VERSION "dbc-export 1 2025.20.8"

NS_ :

BS_:

BU_: APS DAS PARK

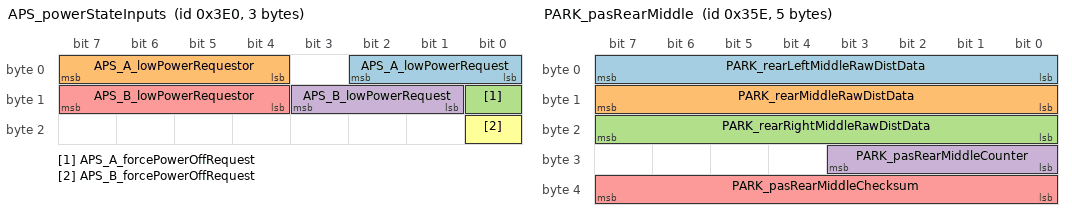
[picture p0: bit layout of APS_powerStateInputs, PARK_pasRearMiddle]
BO_ 992 APS_powerStateInputs: 3 APS
 SG_ APS_A_lowPowerRequest : 0|3@1+ (1,0) [0|7] "" Vector__XXX
 SG_ APS_A_lowPowerRequestor : 4|4@1+ (1,0) [0|15] "" Vector__XXX
 SG_ APS_A_forcePowerOffRequest : 8|1@1+ (1,0) [0|1] "" Vector__XXX
 SG_ APS_B_lowPowerRequest : 9|3@1+ (1,0) [0|7] "" Vector__XXX
 SG_ APS_B_lowPowerRequestor : 12|4@1+ (1,0) [0|15] "" Vector__XXX
 SG_ APS_B_forcePowerOffRequest : 16|1@1+ (1,0) [0|1] "" Vector__XXX

BO_ 586 DAS_visualDebug: 8 DAS
 SG_ DAS_autosteerVehiclesUsage : 4|2@1+ (1,0) [0|3] "" Vector__XXX
 SG_ DAS_autosteerHPPUsage : 6|2@1+ (1,0) [0|3] "" Vector__XXX
 SG_ DAS_autosteerNavigationUsage : 8|2@1+ (1,0) [0|3] "" Vector__XXX
 SG_ DAS_autosteerModelUsage : 10|2@1+ (1,0) [0|3] "" Vector__XXX
 SG_ DAS_autosteerBottsDotsUsage : 12|2@1+ (1,0) [0|3] "" Vector__XXX
 SG_ DAS_offsetSide : 14|2@1+ (1,0) [0|3] "" Vector__XXX
 SG_ DAS_roadSurfaceType : 16|2@1+ (1,0) [1|3] "" Vector__XXX
 SG_ DAS_autosteerHealthAnomalyLevel : 18|3@1+ (1,0) [0|7] "" Vector__XXX
 SG_ DAS_autosteerHealthState : 21|3@1+ (1,0) [0|7] "" Vector__XXX
 SG_ DAS_lastLinePreferenceReason : 24|4@1+ (1,0) [0|15] "" Vector__XXX
 SG_ DAS_plannerState : 28|4@1+ (1,0) [0|15] "" Vector__XXX
 SG_ DAS_lastAutosteerAbortReason : 32|6@1+ (1,0) [0|63] "" Vector__XXX
 SG_ DAS_devAppInterfaceEnabled : 38|1@1+ (1,0) [0|1] "" Vector__XXX
 SG_ DAS_navAvailable : 39|1@1+ (1,0) [0|1] "" Vector__XXX
 SG_ DAS_navDistance : 40|8@1+ (100,0) [0|25500] "km" Vector__XXX
 SG_ DAS_accSmartSpeedActive : 48|1@1+ (1,0) [0|1] "" Vector__XXX
 SG_ DAS_accSmartSpeedState : 49|3@1+ (1,0) [0|6] "" Vector__XXX
 SG_ DAS_ulcInProgress : 52|1@1+ (1,0) [0|1] "" Vector__XXX
 SG_ DAS_trafficAwareSetSpeedInUse : 53|1@1+ (1,0) [0|1] "" Vector__XXX
 SG_ DAS_isaSystemState : 54|2@1+ (1,0) [0|3] "" Vector__XXX
 SG_ DAS_behaviorType : 56|2@1+ (1,0) [0|3] "" Vector__XXX
 SG_ DAS_ulcType : 58|2@1+ (1,0) [0|3] "" Vector__XXX
 SG_ DAS_rearVehDetectedThisCycle : 60|1@1+ (1,0) [0|1] "" Vector__XXX
 SG_ DAS_rearLeftVehDetectedCurrent : 61|1@1+ (1,0) [0|1] "" Vector__XXX
 SG_ DAS_rearRightVehDetectedTrip : 62|1@1+ (1,0) [0|1] "" Vector__XXX
 SG_ DAS_rearLeftVehDetectedTrip : 63|1@1+ (1,0) [0|1] "" Vector__XXX

BO_ 862 PARK_pasRearMiddle: 5 PARK
 SG_ PARK_rearLeftMiddleRawDistData : 0|8@1+ (1,0) [0|254] "cm" Vector__XXX
 SG_ PARK_rearMiddleRawDistData : 8|8@1+ (1,0) [0|254] "cm" Vector__XXX
 SG_ PARK_rearRightMiddleRawDistData : 16|8@1+ (1,0) [0|254] "cm" Vector__XXX
 SG_ PARK_pasRearMiddleCounter : 24|4@1+ (1,0) [0|15] "" Vector__XXX
 SG_ PARK_pasRearMiddleChecksum : 32|8@1+ (1,0) [0|255] "" Vector__XXX

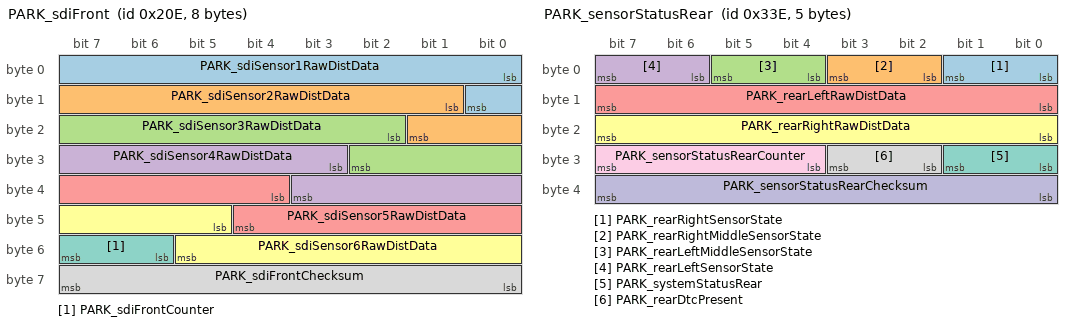
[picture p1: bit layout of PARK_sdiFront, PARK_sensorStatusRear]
BO_ 526 PARK_sdiFront: 8 PARK
 SG_ PARK_sdiSensor1RawDistData : 0|9@1+ (1,0) [0|510] "cm" Vector__XXX
 SG_ PARK_sdiSensor2RawDistData : 9|9@1+ (1,0) [0|510] "cm" Vector__XXX
 SG_ PARK_sdiSensor3RawDistData : 18|9@1+ (1,0) [0|510] "cm" Vector__XXX
 SG_ PARK_sdiSensor4RawDistData : 27|9@1+ (1,0) [0|510] "cm" Vector__XXX
 SG_ PARK_sdiSensor5RawDistData : 36|9@1+ (1,0) [0|510] "cm" Vector__XXX
 SG_ PARK_sdiSensor6RawDistData : 45|9@1+ (1,0) [0|510] "cm" Vector__XXX
 SG_ PARK_sdiFrontCounter : 54|2@1+ (1,0) [0|3] "" Vector__XXX
 SG_ PARK_sdiFrontChecksum : 56|8@1+ (1,0) [0|255] "" Vector__XXX

BO_ 830 PARK_sensorStatusRear: 5 PARK
 SG_ PARK_rearRightSensorState : 0|2@1+ (1,0) [0|2] "" Vector__XXX
 SG_ PARK_rearRightMiddleSensorState : 2|2@1+ (1,0) [0|2] "" Vector__XXX
 SG_ PARK_rearLeftMiddleSensorState : 4|2@1+ (1,0) [0|2] "" Vector__XXX
 SG_ PARK_rearLeftSensorState : 6|2@1+ (1,0) [0|2] "" Vector__XXX
 SG_ PARK_rearLeftRawDistData : 8|8@1+ (1,0) [0|254] "cm" Vector__XXX
 SG_ PARK_rearRightRawDistData : 16|8@1+ (1,0) [0|254] "cm" Vector__XXX
 SG_ PARK_systemStatusRear : 24|2@1+ (1,0) [0|2] "" Vector__XXX
 SG_ PARK_rearDtcPresent : 26|2@1+ (1,0) [0|2] "" Vector__XXX
 SG_ PARK_sensorStatusRearCounter : 28|4@1+ (1,0) [0|15] "" Vector__XXX
 SG_ PARK_sensorStatusRearChecksum : 32|8@1+ (1,0) [0|255] "" Vector__XXX

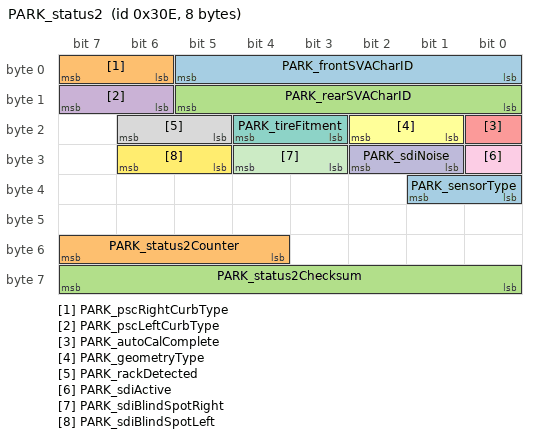
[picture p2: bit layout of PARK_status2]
BO_ 782 PARK_status2: 8 PARK
 SG_ PARK_frontSVACharID : 0|6@1+ (1,0) [0|63] "" Vector__XXX
 SG_ PARK_pscRightCurbType : 6|2@1+ (1,0) [0|3] "" Vector__XXX
 SG_ PARK_rearSVACharID : 8|6@1+ (1,0) [0|63] "" Vector__XXX
 SG_ PARK_pscLeftCurbType : 14|2@1+ (1,0) [0|3] "" Vector__XXX
 SG_ PARK_autoCalComplete : 16|1@1+ (1,0) [0|1] "" Vector__XXX
 SG_ PARK_geometryType : 17|2@1+ (1,0) [0|3] "" Vector__XXX
 SG_ PARK_tireFitment : 19|2@1+ (1,0) [0|2] "" Vector__XXX
 SG_ PARK_rackDetected : 21|2@1+ (1,0) [0|2] "" Vector__XXX
 SG_ PARK_sdiActive : 24|1@1+ (1,0) [0|1] "" Vector__XXX
 SG_ PARK_sdiNoise : 25|2@1+ (1,0) [0|2] "" Vector__XXX
 SG_ PARK_sdiBlindSpotRight : 27|2@1+ (1,0) [0|2] "" Vector__XXX
 SG_ PARK_sdiBlindSpotLeft : 29|2@1+ (1,0) [0|2] "" Vector__XXX
 SG_ PARK_sensorType : 32|2@1+ (1,0) [0|2] "" Vector__XXX
 SG_ PARK_status2Counter : 52|4@1+ (1,0) [0|15] "" Vector__XXX
 SG_ PARK_status2Checksum : 56|8@1+ (1,0) [0|255] "" Vector__XXX

BO_TX_BU_ 992 : APS;
BO_TX_BU_ 586 : DAS;
BO_TX_BU_ 862 : PARK;
BO_TX_BU_ 526 : PARK;
BO_TX_BU_ 830 : PARK;
BO_TX_BU_ 782 : PARK;

CM_ "Tesla Model Y CAN bus database; bus CH (chassis CAN); firmware 2025.20.8. Decoded CAN signal definitions (layout, scaling, units, value tables).";
CM_ BU_ APS "Driver assistance computer (secondary)";
CM_ BU_ DAS "Driver assistance computer";
CM_ BU_ PARK "Parking assist sensors";
CM_ BO_ 992 "Driver assistance computer (secondary) message: power state inputs";
CM_ SG_ 992 APS_A_lowPowerRequest "Indicates Autopilot Secondary Processor (APS) low power state request presence.";
CM_ SG_ 992 APS_A_lowPowerRequestor "Indicates who initiated the Autopilot Secondary Processor (APS) low power request.";
CM_ SG_ 992 APS_A_forcePowerOffRequest "Driver assistance computer (secondary): a force power off request";
CM_ SG_ 992 APS_B_lowPowerRequest "Indicates Autopilot Secondary Processor (APS) low power state request presence.";
CM_ SG_ 992 APS_B_lowPowerRequestor "Indicates who initiated the Autopilot Secondary Processor (APS) low power request.";
CM_ SG_ 992 APS_B_forcePowerOffRequest "Driver assistance computer (secondary): b force power off request";
CM_ BO_ 586 "Driver assistance computer message: visual debug";
CM_ SG_ 586 DAS_autosteerVehiclesUsage "Driver assistance computer: autosteer vehicles usage";
CM_ SG_ 586 DAS_autosteerHPPUsage "Driver assistance computer: autosteer HPP usage";
CM_ SG_ 586 DAS_autosteerNavigationUsage "Driver assistance computer: autosteer navigation usage";
CM_ SG_ 586 DAS_autosteerModelUsage "Driver assistance computer: autosteer model usage";
CM_ SG_ 586 DAS_autosteerBottsDotsUsage "Driver assistance computer: autosteer botts dots usage";
CM_ SG_ 586 DAS_offsetSide "Driver assistance computer: offset side";
CM_ SG_ 586 DAS_roadSurfaceType "Driver assistance computer: road surface type; raw 0 = signal not available (SNA)";
CM_ SG_ 586 DAS_autosteerHealthAnomalyLevel "Driver assistance computer: autosteer health anomaly level";
CM_ SG_ 586 DAS_autosteerHealthState "Driver assistance computer: autosteer health state";
CM_ SG_ 586 DAS_lastLinePreferenceReason "Driver assistance computer: last line preference reason";
CM_ SG_ 586 DAS_plannerState "Driver assistance computer: planner state";
CM_ SG_ 586 DAS_lastAutosteerAbortReason "Driver assistance computer: last autosteer abort reason";
CM_ SG_ 586 DAS_devAppInterfaceEnabled "Driver assistance computer: dev app interface enabled";
CM_ SG_ 586 DAS_navAvailable "Driver assistance computer: nav available";
CM_ SG_ 586 DAS_navDistance "Driver assistance computer: nav distance";
CM_ SG_ 586 DAS_accSmartSpeedActive "Driver assistance computer: acc smart speed active";
CM_ SG_ 586 DAS_accSmartSpeedState "Driver assistance computer: acc smart speed state; raw 7 = signal not available (SNA)";
CM_ SG_ 586 DAS_ulcInProgress "Reports active lane changes that were not commanded.";
CM_ SG_ 586 DAS_trafficAwareSetSpeedInUse "Indicates that autopilot is using cruise set speed based on flow of traffic";
CM_ SG_ 586 DAS_isaSystemState "ISA system state";
CM_ SG_ 586 DAS_behaviorType "Driver assistance computer: behavior type";
CM_ SG_ 586 DAS_ulcType "Reports the underlying reason for the uncommanded lane change, whether for speed or route.";
CM_ SG_ 586 DAS_rearVehDetectedThisCycle "Driver assistance computer: rear veh detected this cycle";
CM_ SG_ 586 DAS_rearLeftVehDetectedCurrent "Driver assistance computer: rear left veh detected current";
CM_ SG_ 586 DAS_rearRightVehDetectedTrip "Driver assistance computer: rear right veh detected trip";
CM_ SG_ 586 DAS_rearLeftVehDetectedTrip "Driver assistance computer: rear left veh detected trip";
CM_ BO_ 862 "Parking assist sensors message: pas rear middle";
CM_ SG_ 862 PARK_rearLeftMiddleRawDistData "Zone defined as -124 degrees to -166 degrees, distance to object in units of centimeters; raw 255 = signal not available (SNA)";
CM_ SG_ 862 PARK_rearMiddleRawDistData "Zone defined as -166 degrees to +166 degrees, distance to object in units of centimeters; raw 255 = signal not available (SNA)";
CM_ SG_ 862 PARK_rearRightMiddleRawDistData "Zone defined as +166 degrees to +124 degrees, distance to object in units of centimeters; raw 255 = signal not available (SNA)";
CM_ SG_ 862 PARK_pasRearMiddleCounter "Parking assist sensors: pas rear middle counter";
CM_ SG_ 862 PARK_pasRearMiddleChecksum "Parking assist sensors: pas rear middle checksum";
CM_ BO_ 526 "Parking assist sensors message: sdi front";
CM_ SG_ 526 PARK_sdiSensor1RawDistData "Parking assist sensors: sdi sensor1 raw dist data; raw 511 = signal not available (SNA)";
CM_ SG_ 526 PARK_sdiSensor2RawDistData "Parking assist sensors: sdi sensor2 raw dist data; raw 511 = signal not available (SNA)";
CM_ SG_ 526 PARK_sdiSensor3RawDistData "Parking assist sensors: sdi sensor3 raw dist data; raw 511 = signal not available (SNA)";
CM_ SG_ 526 PARK_sdiSensor4RawDistData "Parking assist sensors: sdi sensor4 raw dist data; raw 511 = signal not available (SNA)";
CM_ SG_ 526 PARK_sdiSensor5RawDistData "Parking assist sensors: sdi sensor5 raw dist data; raw 511 = signal not available (SNA)";
CM_ SG_ 526 PARK_sdiSensor6RawDistData "Parking assist sensors: sdi sensor6 raw dist data; raw 511 = signal not available (SNA)";
CM_ SG_ 526 PARK_sdiFrontCounter "Parking assist sensors: sdi front counter";
CM_ SG_ 526 PARK_sdiFrontChecksum "Parking assist sensors: sdi front checksum";
CM_ BO_ 830 "Parking assist sensors message: sensor status rear";
CM_ SG_ 830 PARK_rearRightSensorState "Reports the state of the rear right ultrasonic sensor; raw 3 = signal not available (SNA)";
CM_ SG_ 830 PARK_rearRightMiddleSensorState "Reports the state of the rear right middle ultrasonic sensor; raw 3 = signal not available (SNA)";
CM_ SG_ 830 PARK_rearLeftMiddleSensorState "Reports the state of the rear left middle ultrasonic sensor; raw 3 = signal not available (SNA)";
CM_ SG_ 830 PARK_rearLeftSensorState "Reports the state of the rear left ultrasonic sensor; raw 3 = signal not available (SNA)";
CM_ SG_ 830 PARK_rearLeftRawDistData "Zone defined as -90 degrees to -125 degrees, distance to object in units of centimeters; raw 255 = signal not available (SNA)";
CM_ SG_ 830 PARK_rearRightRawDistData "Zone defined as +125 degrees to +90 degrees, distance to object in units of centimeters; raw 255 = signal not available (SNA)";
CM_ SG_ 830 PARK_systemStatusRear "Parking assist sensors: system status rear; raw 3 = signal not available (SNA)";
CM_ SG_ 830 PARK_rearDtcPresent "Parking assist sensors: rear dtc present; raw 3 = signal not available (SNA)";
CM_ SG_ 830 PARK_sensorStatusRearCounter "Parking assist sensors: sensor status rear counter";
CM_ SG_ 830 PARK_sensorStatusRearChecksum "Parking assist sensors: sensor status rear checksum";
CM_ BO_ 782 "Parking assist sensors message: status2";
CM_ SG_ 782 PARK_frontSVACharID "Parking assist sensors: front SVA char ID";
CM_ SG_ 782 PARK_pscRightCurbType "The type of curb for the parallel parking slot on the right side.";
CM_ SG_ 782 PARK_rearSVACharID "Parking assist sensors: rear SVA char ID";
CM_ SG_ 782 PARK_pscLeftCurbType "The type of curb identified for a parallel parking space on the left.";
CM_ SG_ 782 PARK_autoCalComplete "Parking assist sensors: auto cal complete";
CM_ SG_ 782 PARK_geometryType "Parking assist sensors: geometry type";
CM_ SG_ 782 PARK_tireFitment "Parking assist sensors: tire fitment; raw 3 = signal not available (SNA)";
CM_ SG_ 782 PARK_rackDetected "Parking assist sensors: rack detected; raw 3 = signal not available (SNA)";
CM_ SG_ 782 PARK_sdiActive "Whether or not the raw sensor measurements from the ultrasonics are present and valid";
CM_ SG_ 782 PARK_sdiNoise "The output of the noise detection algorithm for raw sensor measurements, indicates if the measurements are degraded due to ambient noise; raw 3 = signal not available (SNA)";
CM_ SG_ 782 PARK_sdiBlindSpotRight "The output of the PARK ECU blindspot algorithm on the right side of the car, indicates the presence of a vehicle; raw 3 = signal not available (SNA)";
CM_ SG_ 782 PARK_sdiBlindSpotLeft "The output of the PARK ECU blindspot algorithm on the left side of the car, indicates the presence of a vehicle; raw 3 = signal not available (SNA)";
CM_ SG_ 782 PARK_sensorType "Parking assist sensors: sensor type; raw 3 = signal not available (SNA)";
CM_ SG_ 782 PARK_status2Counter "Parking assist sensors: status2 counter";
CM_ SG_ 782 PARK_status2Checksum "Parking assist sensors: status2 checksum";
BA_DEF_ "BusType" STRING;
BA_DEF_ "DBName" STRING;
BA_DEF_ "Baudrate" INT 0 1000000;
BA_DEF_ "BaudrateCANFD" INT 0 16000000;
BA_DEF_ "Manufacturer" STRING;
BA_DEF_ "FirmwareVersion" STRING;
BA_DEF_ "VehicleModel" STRING;
BA_DEF_ BU_ "ECU" STRING;
BA_DEF_ BO_ "GenMsgCycleTime" INT 0 3600000;
BA_DEF_ BO_ "GenMsgSendType" ENUM "Cyclic","NotUsed","NotUsed","NotUsed","NotUsed","NotUsed","NotUsed","IfActive","NoMsgSendType","NotUsed";
BA_DEF_ BO_ "VFrameFormat" ENUM "StandardCAN","ExtendedCAN","reserved","J1939PG","reserved","reserved","reserved","reserved","reserved","reserved","reserved","reserved","reserved","reserved","StandardCAN_FD","ExtendedCAN_FD";
BA_DEF_ BO_ "CANFD_BRS" ENUM "0","1";
BA_DEF_ SG_ "GenSigSNA" STRING;
BA_DEF_ SG_ "Confidence" ENUM "validated","plausible","layout-only","contradicted";
BA_DEF_DEF_ "BusType" "CAN";
BA_DEF_DEF_ "DBName" "";
BA_DEF_DEF_ "Baudrate" 500000;
BA_DEF_DEF_ "BaudrateCANFD" 2000000;
BA_DEF_DEF_ "Manufacturer" "";
BA_DEF_DEF_ "FirmwareVersion" "";
BA_DEF_DEF_ "VehicleModel" "";
BA_DEF_DEF_ "ECU" "";
BA_DEF_DEF_ "GenMsgCycleTime" 0;
BA_DEF_DEF_ "GenMsgSendType" "NoMsgSendType";
BA_DEF_DEF_ "VFrameFormat" "StandardCAN";
BA_DEF_DEF_ "CANFD_BRS" "1";
BA_DEF_DEF_ "GenSigSNA" "";
BA_DEF_DEF_ "Confidence" "layout-only";
BA_ "DBName" "ModelY_CH";
BA_ "Manufacturer" "Tesla";
BA_ "FirmwareVersion" "2025.20.8";
BA_ "VehicleModel" "Model Y";
BA_ "ECU" BU_ APS "APS";
BA_ "ECU" BU_ DAS "DAS";
BA_ "ECU" BU_ PARK "PARK";
BA_ "GenMsgCycleTime" BO_ 992 100;
BA_ "GenMsgSendType" BO_ 992 0;
BA_ "GenMsgCycleTime" BO_ 586 100;
BA_ "GenMsgSendType" BO_ 586 0;
BA_ "GenMsgCycleTime" BO_ 862 100;
BA_ "GenMsgSendType" BO_ 862 0;
BA_ "GenMsgCycleTime" BO_ 526 40;
BA_ "GenMsgSendType" BO_ 526 0;
BA_ "GenMsgCycleTime" BO_ 830 100;
BA_ "GenMsgSendType" BO_ 830 0;
BA_ "GenMsgCycleTime" BO_ 782 250;
BA_ "GenMsgSendType" BO_ 782 0;
BA_ "Confidence" SG_ 992 APS_A_lowPowerRequest 0;
BA_ "Confidence" SG_ 992 APS_A_lowPowerRequestor 0;
BA_ "Confidence" SG_ 992 APS_A_forcePowerOffRequest 0;
BA_ "Confidence" SG_ 992 APS_B_lowPowerRequest 0;
BA_ "Confidence" SG_ 992 APS_B_lowPowerRequestor 0;
BA_ "Confidence" SG_ 992 APS_B_forcePowerOffRequest 0;
BA_ "Confidence" SG_ 586 DAS_autosteerVehiclesUsage 0;
BA_ "Confidence" SG_ 586 DAS_autosteerHPPUsage 0;
BA_ "Confidence" SG_ 586 DAS_autosteerNavigationUsage 0;
BA_ "Confidence" SG_ 586 DAS_autosteerModelUsage 0;
BA_ "Confidence" SG_ 586 DAS_autosteerBottsDotsUsage 0;
BA_ "Confidence" SG_ 586 DAS_offsetSide 0;
BA_ "Confidence" SG_ 586 DAS_roadSurfaceType 0;
BA_ "GenSigSNA" SG_ 586 DAS_roadSurfaceType "0";
BA_ "Confidence" SG_ 586 DAS_autosteerHealthAnomalyLevel 0;
BA_ "Confidence" SG_ 586 DAS_autosteerHealthState 0;
BA_ "Confidence" SG_ 586 DAS_lastLinePreferenceReason 0;
BA_ "Confidence" SG_ 586 DAS_plannerState 0;
BA_ "Confidence" SG_ 586 DAS_lastAutosteerAbortReason 0;
BA_ "Confidence" SG_ 586 DAS_devAppInterfaceEnabled 0;
BA_ "Confidence" SG_ 586 DAS_navAvailable 0;
BA_ "Confidence" SG_ 586 DAS_navDistance 0;
BA_ "Confidence" SG_ 586 DAS_accSmartSpeedActive 0;
BA_ "Confidence" SG_ 586 DAS_accSmartSpeedState 0;
BA_ "GenSigSNA" SG_ 586 DAS_accSmartSpeedState "7";
BA_ "Confidence" SG_ 586 DAS_ulcInProgress 0;
BA_ "Confidence" SG_ 586 DAS_trafficAwareSetSpeedInUse 0;
BA_ "Confidence" SG_ 586 DAS_isaSystemState 0;
BA_ "Confidence" SG_ 586 DAS_behaviorType 0;
BA_ "Confidence" SG_ 586 DAS_ulcType 0;
BA_ "Confidence" SG_ 586 DAS_rearVehDetectedThisCycle 0;
BA_ "Confidence" SG_ 586 DAS_rearLeftVehDetectedCurrent 0;
BA_ "Confidence" SG_ 586 DAS_rearRightVehDetectedTrip 0;
BA_ "Confidence" SG_ 586 DAS_rearLeftVehDetectedTrip 0;
BA_ "Confidence" SG_ 862 PARK_rearLeftMiddleRawDistData 0;
BA_ "GenSigSNA" SG_ 862 PARK_rearLeftMiddleRawDistData "255";
BA_ "Confidence" SG_ 862 PARK_rearMiddleRawDistData 0;
BA_ "GenSigSNA" SG_ 862 PARK_rearMiddleRawDistData "255";
BA_ "Confidence" SG_ 862 PARK_rearRightMiddleRawDistData 0;
BA_ "GenSigSNA" SG_ 862 PARK_rearRightMiddleRawDistData "255";
BA_ "Confidence" SG_ 862 PARK_pasRearMiddleCounter 0;
BA_ "Confidence" SG_ 862 PARK_pasRearMiddleChecksum 0;
BA_ "Confidence" SG_ 526 PARK_sdiSensor1RawDistData 0;
BA_ "GenSigSNA" SG_ 526 PARK_sdiSensor1RawDistData "511";
BA_ "Confidence" SG_ 526 PARK_sdiSensor2RawDistData 0;
BA_ "GenSigSNA" SG_ 526 PARK_sdiSensor2RawDistData "511";
BA_ "Confidence" SG_ 526 PARK_sdiSensor3RawDistData 0;
BA_ "GenSigSNA" SG_ 526 PARK_sdiSensor3RawDistData "511";
BA_ "Confidence" SG_ 526 PARK_sdiSensor4RawDistData 0;
BA_ "GenSigSNA" SG_ 526 PARK_sdiSensor4RawDistData "511";
BA_ "Confidence" SG_ 526 PARK_sdiSensor5RawDistData 0;
BA_ "GenSigSNA" SG_ 526 PARK_sdiSensor5RawDistData "511";
BA_ "Confidence" SG_ 526 PARK_sdiSensor6RawDistData 0;
BA_ "GenSigSNA" SG_ 526 PARK_sdiSensor6RawDistData "511";
BA_ "Confidence" SG_ 526 PARK_sdiFrontCounter 0;
BA_ "Confidence" SG_ 526 PARK_sdiFrontChecksum 0;
BA_ "Confidence" SG_ 830 PARK_rearRightSensorState 0;
BA_ "GenSigSNA" SG_ 830 PARK_rearRightSensorState "3";
BA_ "Confidence" SG_ 830 PARK_rearRightMiddleSensorState 0;
BA_ "GenSigSNA" SG_ 830 PARK_rearRightMiddleSensorState "3";
BA_ "Confidence" SG_ 830 PARK_rearLeftMiddleSensorState 0;
BA_ "GenSigSNA" SG_ 830 PARK_rearLeftMiddleSensorState "3";
BA_ "Confidence" SG_ 830 PARK_rearLeftSensorState 0;
BA_ "GenSigSNA" SG_ 830 PARK_rearLeftSensorState "3";
BA_ "Confidence" SG_ 830 PARK_rearLeftRawDistData 0;
BA_ "GenSigSNA" SG_ 830 PARK_rearLeftRawDistData "255";
BA_ "Confidence" SG_ 830 PARK_rearRightRawDistData 0;
BA_ "GenSigSNA" SG_ 830 PARK_rearRightRawDistData "255";
BA_ "Confidence" SG_ 830 PARK_systemStatusRear 0;
BA_ "GenSigSNA" SG_ 830 PARK_systemStatusRear "3";
BA_ "Confidence" SG_ 830 PARK_rearDtcPresent 0;
BA_ "GenSigSNA" SG_ 830 PARK_rearDtcPresent "3";
BA_ "Confidence" SG_ 830 PARK_sensorStatusRearCounter 0;
BA_ "Confidence" SG_ 830 PARK_sensorStatusRearChecksum 0;
BA_ "Confidence" SG_ 782 PARK_frontSVACharID 0;
BA_ "Confidence" SG_ 782 PARK_pscRightCurbType 0;
BA_ "Confidence" SG_ 782 PARK_rearSVACharID 0;
BA_ "Confidence" SG_ 782 PARK_pscLeftCurbType 0;
BA_ "Confidence" SG_ 782 PARK_autoCalComplete 0;
BA_ "Confidence" SG_ 782 PARK_geometryType 0;
BA_ "Confidence" SG_ 782 PARK_tireFitment 0;
BA_ "GenSigSNA" SG_ 782 PARK_tireFitment "3";
BA_ "Confidence" SG_ 782 PARK_rackDetected 0;
BA_ "GenSigSNA" SG_ 782 PARK_rackDetected "3";
BA_ "Confidence" SG_ 782 PARK_sdiActive 0;
BA_ "Confidence" SG_ 782 PARK_sdiNoise 0;
BA_ "GenSigSNA" SG_ 782 PARK_sdiNoise "3";
BA_ "Confidence" SG_ 782 PARK_sdiBlindSpotRight 0;
BA_ "GenSigSNA" SG_ 782 PARK_sdiBlindSpotRight "3";
BA_ "Confidence" SG_ 782 PARK_sdiBlindSpotLeft 0;
BA_ "GenSigSNA" SG_ 782 PARK_sdiBlindSpotLeft "3";
BA_ "Confidence" SG_ 782 PARK_sensorType 0;
BA_ "GenSigSNA" SG_ 782 PARK_sensorType "3";
BA_ "Confidence" SG_ 782 PARK_status2Counter 0;
BA_ "Confidence" SG_ 782 PARK_status2Checksum 0;
VAL_ 992 APS_A_lowPowerRequest 5 "APS_LOW_POWER_COLD_RESET" 4 "APS_LOW_POWER_SOC_WARM_RESET" 3 "APS_LOW_POWER_AP_WARM_RESET" 2 "APS_LOW_POWER_OFF" 1 "APS_LOW_POWER_SUSPEND" 0 "APS_LOW_POWER_NONE" ;
VAL_ 992 APS_A_lowPowerRequestor 10 "APS_LOW_POWER_REQ_COUNT" 9 "APS_LOW_POWER_REQ_SGK_PGOOD_IRQ" 8 "APS_LOW_POWER_REQ_SGK_CONSOLE" 7 "APS_LOW_POWER_REQ_SGK_SLEEP" 6 "APS_LOW_POWER_REQ_SGK_UDS" 5 "APS_LOW_POWER_REQ_SGK_BRIDGE" 4 "APS_LOW_POWER_REQ_SGK_FM" 3 "APS_LOW_POWER_REQ_SGK_POWER" 2 "APS_LOW_POWER_REQ_AP_MAILBOX" 1 "APS_LOW_POWER_REQ_AP_ATF" 0 "APS_LOW_POWER_REQ_NONE" ;
VAL_ 992 APS_B_lowPowerRequest 5 "APS_LOW_POWER_COLD_RESET" 4 "APS_LOW_POWER_SOC_WARM_RESET" 3 "APS_LOW_POWER_AP_WARM_RESET" 2 "APS_LOW_POWER_OFF" 1 "APS_LOW_POWER_SUSPEND" 0 "APS_LOW_POWER_NONE" ;
VAL_ 992 APS_B_lowPowerRequestor 10 "APS_LOW_POWER_REQ_COUNT" 9 "APS_LOW_POWER_REQ_SGK_PGOOD_IRQ" 8 "APS_LOW_POWER_REQ_SGK_CONSOLE" 7 "APS_LOW_POWER_REQ_SGK_SLEEP" 6 "APS_LOW_POWER_REQ_SGK_UDS" 5 "APS_LOW_POWER_REQ_SGK_BRIDGE" 4 "APS_LOW_POWER_REQ_SGK_FM" 3 "APS_LOW_POWER_REQ_SGK_POWER" 2 "APS_LOW_POWER_REQ_AP_MAILBOX" 1 "APS_LOW_POWER_REQ_AP_ATF" 0 "APS_LOW_POWER_REQ_NONE" ;
VAL_ 586 DAS_autosteerVehiclesUsage 3 "BLACKLISTED" 2 "FUSED" 1 "AVAILABLE" 0 "REJECTED_UNAVAILABLE" ;
VAL_ 586 DAS_autosteerHPPUsage 3 "BLACKLISTED" 2 "FUSED" 1 "AVAILABLE" 0 "REJECTED_UNAVAILABLE" ;
VAL_ 586 DAS_autosteerNavigationUsage 3 "BLACKLISTED" 2 "FUSED" 1 "AVAILABLE" 0 "REJECTED_UNAVAILABLE" ;
VAL_ 586 DAS_autosteerModelUsage 3 "BLACKLISTED" 2 "FUSED" 1 "AVAILABLE" 0 "REJECTED_UNAVAILABLE" ;
VAL_ 586 DAS_autosteerBottsDotsUsage 3 "BLACKLISTED" 2 "FUSED" 1 "AVAILABLE" 0 "REJECTED_UNAVAILABLE" ;
VAL_ 586 DAS_offsetSide 3 "OFFSET_BOTH_OBJECTS" 2 "OFFSET_LEFT_OBJECT" 1 "OFFSET_RIGHT_OBJECT" 0 "NO_OFFSET" ;
VAL_ 586 DAS_roadSurfaceType 2 "ROAD_SURFACE_ENHANCED" 1 "ROAD_SURFACE_NORMAL" 0 "ROAD_SURFACE_SNA" ;
VAL_ 586 DAS_autosteerHealthState 5 "HEALTH_FAULT" 4 "HEALTH_ABORTING" 3 "HEALTH_SEVERELY_DEGRADED" 2 "HEALTH_DEGRADED" 1 "HEALTH_NOMINAL" 0 "HEALTH_UNAVAILABLE" ;
VAL_ 586 DAS_lastLinePreferenceReason 15 "NONE" 5 "COUNTRY_DRIVING_SIDE" 4 "AVOID_ONCOMING_LANES" 3 "NAVIGATION_BRANCH" 2 "NEIGHBOR_LANE_PROBABILIY" 1 "AGREEMENT_WITH_NEIGHBOR_LANES" 0 "OTHER_LANE_DISAGREES_WITH_MODEL" ;
VAL_ 586 DAS_plannerState 7 "TP_EXTSTATE_LANECHANGE_ABORT" 6 "TP_EXTSTATE_LANECHANGE_WAIT_FOR_FWD_OBSTACLE" 5 "TP_EXTSTATE_LANECHANGE_WAIT_FOR_SIDE_OBSTACLE" 4 "TP_EXTSTATE_LANECHANGE_IN_PROGRESS" 3 "TP_EXTSTATE_LANECHANGE_REQUESTED" 2 "TP_EXTSTATE_FOLLOW" 1 "TP_EXTSTATE_VL" 0 "TP_EXTSTATE_DISABLED" ;
VAL_ 586 DAS_lastAutosteerAbortReason 36 "UI_ABORT_REASON_AHB_MANUAL_OVERRIDE" 35 "UI_ABORT_REASON_DRIVER_NOT_PRESENT" 34 "UI_ABORT_REASON_USER_OVERRIDE_STRIKEOUT" 33 "UI_ABORT_REASON_SEATBELT_UNBUCKLED" 32 "UI_ABORT_REASON_AEB" 31 "UI_ABORT_REASON_NO_ABORT" 30 "UI_ABORT_REASON_CAMERA_FAILSAFES" 29 "UI_ABORT_REASON_ACC_CANCEL" 28 "UI_ABORT_REASON_EPAS_ERROR_CODE" 27 "UI_ABORT_REASON_PLANNER_OUTPUT_INVALID" 26 "UI_ABORT_REASON_FOLLOWER_OUTPUT_INVALID" 25 "UI_ABORT_REASON_VEHICLE_SPEED_ABOVE_MAX" 24 "UI_ABORT_REASON_DRIVING_OFF_NAV" 23 "UI_ABORT_REASON_CID_SWITCH_DISABLED" 22 "UI_ABORT_REASON_CRUISE_FAULT" 21 "UI_ABORT_REASON_COMPONENT_MIA" 20 "UI_ABORT_REASON_EPAS_EAC_DENIED" 19 "UI_ABORT_REASON_SIDE_COLLISION_IMMINENT" 18 "UI_ABORT_REASON_TRAILER_MODE" 17 "UI_ABORT_REASON_CAM_WATCHDOG" 16 "UI_ABORT_REASON_CAM_MSG_MIA" 15 "UI_ABORT_REASON_ME_MAIN_STATE_NOT_VISION" 14 "UI_ABORT_REASON_APP_ME_STATE_NOT_VISION" 2 "UI_ABORT_REASON_HM_STEERING_ERROR" 1 "UI_ABORT_REASON_HM_VIRTUAL_LANE_NO_INPUTS" 0 "UI_ABORT_REASON_HM_LANE_VIEW_RANGE" ;
VAL_ 586 DAS_navAvailable 1 "DAS_NAV_AVAILABLE" 0 "DAS_NAV_UNAVAILABLE" ;
VAL_ 586 DAS_accSmartSpeedState 7 "SNA" 5 "OFFRAMP_DELAY" 4 "SET_SPEED_SET_REQUESTED" 3 "ACTIVE_ONRAMP" 2 "ACTIVE_INTEGRATING" 1 "ACTIVE_OFFRAMP" 0 "NOT_ACTIVE" ;
VAL_ 586 DAS_ulcInProgress 1 "ULC_ACTIVE" 0 "ULC_INACTIVE" ;
VAL_ 586 DAS_isaSystemState 3 "ISA_UNAVAILABLE" 2 "ISA_INVALID" 1 "ISA_ASSUMED_LIMITS" 0 "ISA_NOMINAL" ;
VAL_ 586 DAS_behaviorType 3 "DAS_BEHAVIOR_LANE_CHANGE_RIGHT" 2 "DAS_BEHAVIOR_LANE_CHANGE_LEFT" 1 "DAS_BEHAVIOR_IN_LANE" 0 "DAS_BEHAVIOR_INVALID" ;
VAL_ 586 DAS_ulcType 2 "ULC_TYPE_SPEED" 1 "ULC_TYPE_NAV" 0 "ULC_TYPE_NONE" ;
VAL_ 586 DAS_rearVehDetectedThisCycle 1 "VEHICLE_DETECTED" 0 "VEHICLE_NOT_DETECTED" ;
VAL_ 586 DAS_rearLeftVehDetectedCurrent 1 "VEHICLE_DETECTED" 0 "VEHICLE_NOT_DETECTED" ;
VAL_ 586 DAS_rearRightVehDetectedTrip 1 "VEHICLE_DETECTED" 0 "VEHICLE_NOT_DETECTED" ;
VAL_ 586 DAS_rearLeftVehDetectedTrip 1 "VEHICLE_DETECTED" 0 "VEHICLE_NOT_DETECTED" ;
VAL_ 862 PARK_rearLeftMiddleRawDistData 255 "SNA" ;
VAL_ 862 PARK_rearMiddleRawDistData 255 "SNA" ;
VAL_ 862 PARK_rearRightMiddleRawDistData 255 "SNA" ;
VAL_ 526 PARK_sdiSensor1RawDistData 511 "SNA" 500 "NO_OBJECT_DETECTED" 1 "NEAR_DETECTION" 0 "BLOCKED" ;
VAL_ 526 PARK_sdiSensor2RawDistData 511 "SNA" 500 "NO_OBJECT_DETECTED" 1 "NEAR_DETECTION" 0 "BLOCKED" ;
VAL_ 526 PARK_sdiSensor3RawDistData 511 "SNA" 500 "NO_OBJECT_DETECTED" 1 "NEAR_DETECTION" 0 "BLOCKED" ;
VAL_ 526 PARK_sdiSensor4RawDistData 511 "SNA" 500 "NO_OBJECT_DETECTED" 1 "NEAR_DETECTION" 0 "BLOCKED" ;
VAL_ 526 PARK_sdiSensor5RawDistData 511 "SNA" 500 "NO_OBJECT_DETECTED" 1 "NEAR_DETECTION" 0 "BLOCKED" ;
VAL_ 526 PARK_sdiSensor6RawDistData 511 "SNA" 500 "NO_OBJECT_DETECTED" 1 "NEAR_DETECTION" 0 "BLOCKED" ;
VAL_ 830 PARK_rearRightSensorState 3 "SNA" 2 "TEMPORARY_FAILURE" 1 "PERMANENT_FAILURE" 0 "NO_FAILURE" ;
VAL_ 830 PARK_rearRightMiddleSensorState 3 "SNA" 2 "TEMPORARY_FAILURE" 1 "PERMANENT_FAILURE" 0 "NO_FAILURE" ;
VAL_ 830 PARK_rearLeftMiddleSensorState 3 "SNA" 2 "TEMPORARY_FAILURE" 1 "PERMANENT_FAILURE" 0 "NO_FAILURE" ;
VAL_ 830 PARK_rearLeftSensorState 3 "SNA" 2 "TEMPORARY_FAILURE" 1 "PERMANENT_FAILURE" 0 "NO_FAILURE" ;
VAL_ 830 PARK_rearLeftRawDistData 255 "SNA" ;
VAL_ 830 PARK_rearRightRawDistData 255 "SNA" ;
VAL_ 830 PARK_systemStatusRear 3 "SNA" 2 "UNUSED" 1 "ENABLED" 0 "DISABLED" ;
VAL_ 830 PARK_rearDtcPresent 3 "SNA" 2 "UNUSED" 1 "TRUE" 0 "FALSE" ;
VAL_ 782 PARK_pscRightCurbType 2 "HIGH_CURB" 1 "LOW_CURB" 0 "VIRTUAL_CURB" ;
VAL_ 782 PARK_pscLeftCurbType 2 "HIGH_CURB" 1 "LOW_CURB" 0 "VIRTUAL_CURB" ;
VAL_ 782 PARK_autoCalComplete 1 "COMPLETE" 0 "INCOMPLETE" ;
VAL_ 782 PARK_geometryType 3 "MODELY" 2 "MODEL3" 1 "MODELX" 0 "MODELS" ;
VAL_ 782 PARK_tireFitment 3 "SNA" 2 "NOT_USED" 1 "STAGGERED" 0 "SQUARE" ;
VAL_ 782 PARK_rackDetected 3 "SNA" 2 "RACK_DETECTED" 1 "NO_RACK" 0 "UNKNOWN" ;
VAL_ 782 PARK_sdiActive 1 "SDI_ENABLED" 0 "SDI_DISABLED" ;
VAL_ 782 PARK_sdiNoise 3 "SDI_NOISE_SNA" 2 "SDI_NOISE_RAIN" 1 "SDI_NOISE_HIGH" 0 "SDI_NOISE_NOMINAL" ;
VAL_ 782 PARK_sdiBlindSpotRight 3 "SNA" 2 "UNUSED" 1 "WARNING" 0 "NO_WARNING" ;
VAL_ 782 PARK_sdiBlindSpotLeft 3 "SNA" 2 "UNUSED" 1 "WARNING" 0 "NO_WARNING" ;
VAL_ 782 PARK_sensorType 3 "SNA" 2 "VALEO_HP" 1 "VALEO_HPFL" 0 "NONE" ;
